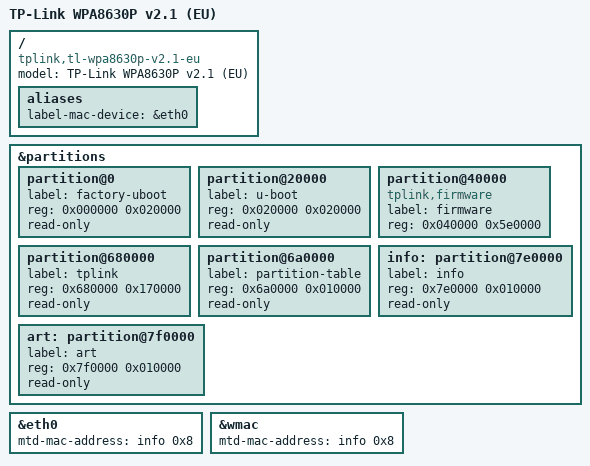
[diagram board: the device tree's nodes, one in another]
// SPDX-License-Identifier: GPL-2.0-or-later OR MIT
/dts-v1/;

#include "qca9563_tplink_tl-wpa8630.dtsi"

/ {
	compatible = "tplink,tl-wpa8630p-v2.1-eu", "qca,qca9563";
	model = "TP-Link WPA8630P v2.1 (EU)";

	aliases {
		label-mac-device = &eth0;
	};
};

&partitions {
	partition@0 {
		label = "factory-uboot";
		reg = <0x000000 0x020000>;
		read-only;
	};

	partition@20000 {
		label = "u-boot";
		reg = <0x020000 0x020000>;
		read-only;
	};

	partition@40000 {
		compatible = "tplink,firmware";
		label = "firmware";
		reg = <0x040000 0x5e0000>;
	};

	partition@680000 {
		label = "tplink";
		reg = <0x680000 0x170000>;
		read-only;
	};

	partition@6a0000 {
		label = "partition-table";
		reg = <0x6a0000 0x010000>;
		read-only;
	};

	info: partition@7e0000 {
		label = "info";
		reg = <0x7e0000 0x010000>;
		read-only;
	};

	art: partition@7f0000 {
		label = "art";
		reg = <0x7f0000 0x010000>;
		read-only;
	};
};

&eth0 {
	mtd-mac-address = <&info 0x8>;
};

&wmac {
	mtd-mac-address = <&info 0x8>;
};
